# C2000_M3_USB_Type0_Registers register map
Vendor: Texas Instruments
Peripheral module from a debugger description file (folder C2000).
Address unit: 16 bits
Registers are 8-bit, read-write, no defined reset value unless marked. A register's access mark holds for its fields unless they carry their own. Offsets are as the file gives them; lines under a group give offsets from that group; [hi:lo] are bit positions; {n}, {i} and the like mark numbered series; 'fields as' and 'values as' point back to an identical list; <NAME> marks a mode.

## USB0 — Univeral Serial Bus register offsets
0x00 USB_FADDR — USB Device Functional Address
  [6:0] USB_FADDR — Function Address
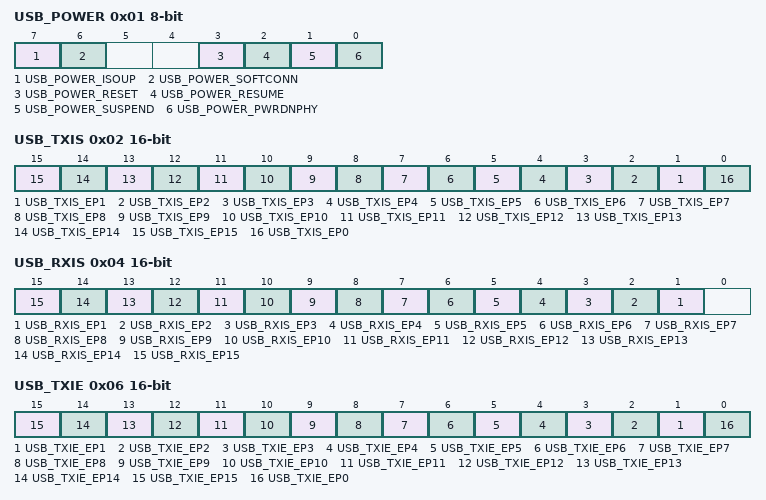
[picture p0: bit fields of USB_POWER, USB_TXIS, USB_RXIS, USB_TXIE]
0x01 USB_POWER
  [7] USB_POWER_ISOUP — Isochronous Update
  [6] USB_POWER_SOFTCONN — Soft Connect/Disconnect
  [3] USB_POWER_RESET — RESET Signaling
  [2] USB_POWER_RESUME — RESUME Signaling
  [1] USB_POWER_SUSPEND — SUSPEND Mode
  [0] USB_POWER_PWRDNPHY — Power Down PHY
0x02 USB_TXIS 16-bit ro — USB Transmit Interrupt Status
  [n] USB_TXIS_EP{n} (n=1..15) — TX Endpoint {n} Interrupt
  [0] USB_TXIS_EP0 — TX and RX Endpoint 0 Interrupt
0x04 USB_RXIS 16-bit ro — USB Receive Interrupt Status
  [n] USB_RXIS_EP{n} (n=1..15) — RX Endpoint {n} Interrupt
0x06 USB_TXIE 16-bit — USB Transmit Interrupt Enable
  [n] USB_TXIE_EP{n} (n=1..15) — TX Endpoint {n} Interrupt Enable
  [0] USB_TXIE_EP0 — TX and RX Endpoint 0 Interrupt Enable
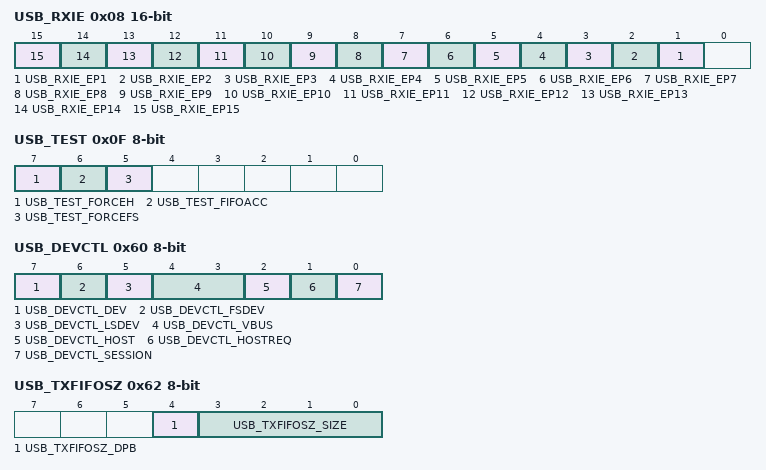
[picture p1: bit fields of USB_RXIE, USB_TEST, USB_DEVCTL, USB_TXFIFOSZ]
0x08 USB_RXIE 16-bit — USB Receive Interrupt Enable
  [n] USB_RXIE_EP{n} (n=1..15) — RX Endpoint {n} Interrupt Enable
0x0A USB_IS ro — USB General Interrupt Status
  [7] USB_IS_VBUSERR — VBUS Error
  [6] USB_IS_SESREQ — SESSION REQUEST
  [5] USB_IS_DISCON — Session Disconnect
  [4] USB_IS_CONN — Session Connect
  [3] USB_IS_SOF — Start of Frame
  [2] USB_IS_BABBLE — Babble Detected
  [2] USB_IS_RESET — RESET Signaling Detected
  [1] USB_IS_RESUME — RESUME Signaling Detected
  [0] USB_IS_SUSPEND — SUSPEND Signaling Detected
0x0B USB_IE — USB Interrupt Enable
  [7] USB_IE_VBUSERR — Enable VBUS Error Interrupt
  [6] USB_IE_SESREQ — Enable Session Request
  [5] USB_IE_DISCON — Enable Disconnect Interrupt
  [4] USB_IE_CONN — Enable Connect Interrupt
  [3] USB_IE_SOF — Enable Start-of-Frame Interrupt
  [2] USB_IE_BABBLE — Enable Babble Interrupt
  [2] USB_IE_RESET — Enable RESET Interrupt
  [1] USB_IE_RESUME — Enable RESUME Interrupt
  [0] USB_IE_SUSPND — Enable SUSPEND Interrupt
0x0C USB_FRAME 16-bit ro — USB Frame Value
  [10:0] USB_FRAME — Frame Number
0x0E USB_EPIDX — USB Endpoint Index
  [3:0] USB_EPIDX_EPIDX — Endpoint Index
0x0F USB_TEST — USB Test Mode
  [7] USB_TEST_FORCEH — Force Host Mode
  [6] USB_TEST_FIFOACC — FIFO Access
  [5] USB_TEST_FORCEFS — Force Full-Speed Mode
{0x20+4i} USB_FIFO{i} 32-bit (i=0..15) — USB FIFO Endpoint {i}
  [31:0] USB_FIFO{i}_EPDATA — Endpoint Data
0x60 USB_DEVCTL — USB Device Control
  [7] USB_DEVCTL_DEV — Device Mode
  [6] USB_DEVCTL_FSDEV — Full-Speed Device Detected
  [5] USB_DEVCTL_LSDEV — Low-Speed Device Detected
  [4:3] USB_DEVCTL_VBUS — VBUS Level
    0=USB_DEVCTL_VBUS_NONE (Below SessionEnd); 1=USB_DEVCTL_VBUS_SEND (Above SessionEnd, below AValid); 2=USB_DEVCTL_VBUS_AVALID (Above AValid, below VBUSValid); 3=USB_DEVCTL_VBUS_VALID (Above VBUSValid)
  [2] USB_DEVCTL_HOST — Host Mode
  [1] USB_DEVCTL_HOSTREQ — Host Request
  [0] USB_DEVCTL_SESSION — Session Start/End
0x62 USB_TXFIFOSZ — USB Transmit Dynamic FIFO Sizing
  [4] USB_TXFIFOSZ_DPB — Double Packet Buffer Support
  [3:0] USB_TXFIFOSZ_SIZE — Max Packet Size
    0=8; 1=16; 2=32; 3=64; 4=128; 5=256; 6=512; 7=1024; 8=2048
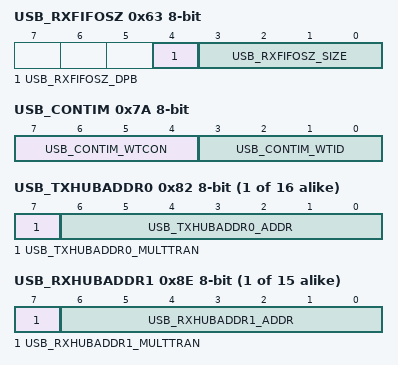
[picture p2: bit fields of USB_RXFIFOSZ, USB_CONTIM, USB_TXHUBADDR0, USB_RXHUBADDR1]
0x63 USB_RXFIFOSZ — USB Receive Dynamic FIFO Sizing
  [4] USB_RXFIFOSZ_DPB — Double Packet Buffer Support
  [3:0] USB_RXFIFOSZ_SIZE — Max Packet Size
    0=8; 1=16; 2=32; 3=64; 4=128; 5=256; 6=512; 7=1024; 8=2048
0x64 USB_TXFIFOADD 16-bit — USB Transmit FIFO Start Address
  [8:0] USB_TXFIFOADD_ADDR — Transmit/Receive Start Address
0x66 USB_RXFIFOADD 16-bit — USB Receive FIFO Start Address
  [8:0] USB_RXFIFOADD_ADDR — Transmit/Receive Start Address
0x7A USB_CONTIM — USB Connect Timing
  [7:4] USB_CONTIM_WTCON — Connect Wait
  [3:0] USB_CONTIM_WTID — Wait ID
0x7B USB_VPLEN — USB OTG VBUS Pulse Timing
  [7:0] USB_VPLEN_VPLEN — VBUS Pulse Length
0x7D USB_FSEOF — USB Full-Speed Last Transaction to End of Frame Timing
  [7:0] USB_FSEOF_FSEOFG — Full-Speed End-of-Frame Gap
0x7E USB_LSEOF — USB Low-Speed Last Transaction to End of Frame Timing
  [7:0] USB_LSEOF_LSEOFG — Low-Speed End-of-Frame Gap
{0x80+8i} USB_TXFUNCADDR{i} (i=0..15) — USB Transmit Functional Address Endpoint {i}
  [6:0] USB_TXFUNCADDR{i}_ADDR — Device Address
{0x82+8i} USB_TXHUBADDR{i} (i=0..15) — USB Transmit Hub Address Endpoint {i}
  [7] USB_TXHUBADDR{i}_MULTTRAN — Multiple Translators
  [6:0] USB_TXHUBADDR{i}_ADDR — Hub Address
{0x83+8i} USB_TXHUBPORT{i} (i=0..15) — USB Transmit Hub Port Endpoint {i}
  [6:0] USB_TXHUBPORT{i}_PORT — Hub Port
{0x84+8i} USB_RXFUNCADDR{i} (i=1..15) — USB Receive Functional Address Endpoint {i}
  [6:0] USB_RXFUNCADDR{i}_ADDR — Device Address
{0x86+8i} USB_RXHUBADDR{i} (i=1..15) — USB Receive Hub Address Endpoint {i}
  [7] USB_RXHUBADDR{i}_MULTTRAN — Multiple Translators
  [6:0] USB_RXHUBADDR{i}_ADDR — Hub Address
{0x87+8i} USB_RXHUBPORT{i} (i=1..15) — USB Receive Hub Port Endpoint {i}
  [6:0] USB_RXHUBPORT{i}_PORT — Hub Port
0x102 USB_CSRL0 wo — USB Control and Status Endpoint 0 Low
  [7] USB_CSRL0_NAKTO — NAK Timeout
  [7] USB_CSRL0_SETENDC — Setup End Clear
  [6] USB_CSRL0_STATUS — STATUS Packet
  [6] USB_CSRL0_RXRDYC — RXRDY Clear
  [5] USB_CSRL0_REQPKT — Request Packet
  [5] USB_CSRL0_STALL — Send Stall
  [4] USB_CSRL0_SETEND — Setup End
  [4] USB_CSRL0_ERROR — Error
  [3] USB_CSRL0_DATAEND — Data End
  [3] USB_CSRL0_SETUP — Setup Packet
  [2] USB_CSRL0_STALLED — Endpoint Stalled
  [1] USB_CSRL0_TXRDY — Transmit Packet Ready
  [0] USB_CSRL0_RXRDY — Receive Packet Ready
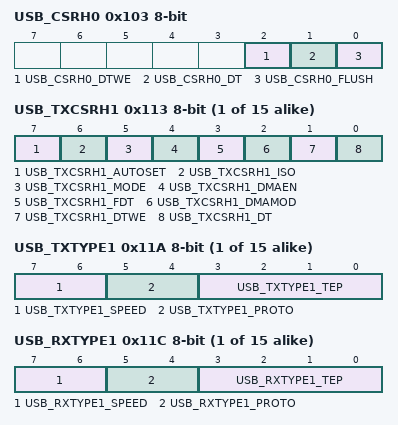
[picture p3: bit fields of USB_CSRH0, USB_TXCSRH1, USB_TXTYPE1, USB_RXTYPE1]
0x103 USB_CSRH0 wo — USB Control and Status Endpoint 0 High
  [2] USB_CSRH0_DTWE — Data Toggle Write Enable
  [1] USB_CSRH0_DT — Data Toggle
  [0] USB_CSRH0_FLUSH — Flush FIFO
0x108 USB_COUNT0 ro — USB Receive Byte Count Endpoint 0
  [6:0] USB_COUNT0_COUNT — FIFO Count
0x10A USB_TYPE0 — USB Type Endpoint 0
  [7:6] USB_TYPE0_SPEED — Operating Speed
    2=USB_TYPE0_SPEED_FULL (Full); 3=USB_TYPE0_SPEED_LOW (Low)
0x10B USB_NAKLMT — USB NAK Limit
  [4:0] USB_NAKLMT_NAKLMT — EP0 NAK Limit
{0x100+0x10*i} USB_TXMAXP{i} 16-bit (i=1..15) — USB Maximum Transmit Data Endpoint {i}
  [10:0] USB_TXMAXP{i}_MAXLOAD — Maximum Payload
0x112 USB_TXCSRL1 — USB Transmit Control and Status Endpoint 1 Low
  [7] USB_TXCSRL1_NAKTO — NAK Timeout
  [6] USB_TXCSRL1_CLRDT — Clear Data Toggle
  [5] USB_TXCSRL1_STALLED — Endpoint Stalled
  [4] USB_TXCSRL1_STALL — Send STALL
  [4] USB_TXCSRL1_SETUP — Setup Packet
  [3] USB_TXCSRL1_FLUSH — Flush FIFO
  [2] USB_TXCSRL1_ERROR — Error
  [2] USB_TXCSRL1_UNDRN — Underrun
  [1] USB_TXCSRL1_FIFONE — FIFO Not Empty
  [0] USB_TXCSRL1_TXRDY — Transmit Packet Ready
{0x103+0x10*i} USB_TXCSRH{i} (i=1..15) — USB Transmit Control and Status Endpoint {i} High
  [7] USB_TXCSRH{i}_AUTOSET — Auto Set
  [6] USB_TXCSRH{i}_ISO — Isochronous Transfers
  [5] USB_TXCSRH{i}_MODE — Mode
  [4] USB_TXCSRH{i}_DMAEN — DMA Request Enable
  [3] USB_TXCSRH{i}_FDT — Force Data Toggle
  [2] USB_TXCSRH{i}_DMAMOD — DMA Request Mode
  [1] USB_TXCSRH{i}_DTWE — Data Toggle Write Enable
  [0] USB_TXCSRH{i}_DT — Data Toggle
{0x104+0x10*i} USB_RXMAXP{i} 16-bit (i=1..15) — USB Maximum Receive Data Endpoint {i}
  [10:0] USB_RXMAXP{i}_MAXLOAD — Maximum Payload
0x116 USB_RXCSRL1 — USB Receive Control and Status Endpoint 1 Low
  [7] USB_RXCSRL1_CLRDT — Clear Data Toggle
  [6] USB_RXCSRL1_STALLED — Endpoint Stalled
  [5] USB_RXCSRL1_STALL — Send STALL
  [5] USB_RXCSRL1_REQPKT — Request Packet
  [4] USB_RXCSRL1_FLUSH — Flush FIFO
  [3] USB_RXCSRL1_DATAERR — Data Error
  [3] USB_RXCSRL1_NAKTO — NAK Timeout
  [2] USB_RXCSRL1_OVER — Overrun
  [2] USB_RXCSRL1_ERROR — Error
  [1] USB_RXCSRL1_FULL — FIFO Full
  [0] USB_RXCSRL1_RXRDY — Receive Packet Ready
{0x107+0x10*i} USB_RXCSRH{i} (i=1..6) — USB Receive Control and Status Endpoint {i} High
  [7] USB_RXCSRH{i}_AUTOCL — Auto Clear
  [6] USB_RXCSRH{i}_AUTORQ — Auto Request
  [6] USB_RXCSRH{i}_ISO — Isochronous Transfers
  [5] USB_RXCSRH{i}_DMAEN — DMA Request Enable
  [4] USB_RXCSRH{i}_DISNYET — Disable NYET
  [4] USB_RXCSRH{i}_PIDERR — PID Error
  [3] USB_RXCSRH{i}_DMAMOD — DMA Request Mode
  [2] USB_RXCSRH{i}_DTWE — Data Toggle Write Enable
  [1] USB_RXCSRH{i}_DT — Data Toggle
{0x108+0x10*i} USB_RXCOUNT{i} 16-bit ro (i=1..15) — USB Receive Byte Count Endpoint {i}
  [12:0] USB_RXCOUNT{i}_COUNT — Receive Packet Count
{0x10A+0x10*i} USB_TXTYPE{i} (i=1..15) — USB Host Transmit Configure Type Endpoint {i}
  [7:6] USB_TXTYPE{i}_SPEED — Operating Speed
    0=USB_TXTYPE{i}_SPEED_DFLT (Default); 2=USB_TXTYPE{i}_SPEED_FULL (Full); 3=USB_TXTYPE{i}_SPEED_LOW (Low)
  [5:4] USB_TXTYPE{i}_PROTO — Protocol
    0=USB_TXTYPE{i}_PROTO_CTRL (Control); 1=USB_TXTYPE{i}_PROTO_ISOC (Isochronous); 2=USB_TXTYPE{i}_PROTO_BULK (Bulk); 3=USB_TXTYPE{i}_PROTO_INT (Interrupt)
  [3:0] USB_TXTYPE{i}_TEP — Target Endpoint Number
{0x10B+0x10*i} USB_TXINTERVAL{i} (i=1..15) — USB Host Transmit Interval Endpoint {i}
  [7:0] USB_TXINTERVAL{i}_TXPOLL — TX Polling
{0x10B+0x10*i} USB_TXINTERVAL{i} (i=1..15) — USB Host Transmit Interval Endpoint {i}
  [7:0] USB_TXINTERVAL{i}_NAKLMT — NAK Limit
{0x10C+0x10*i} USB_RXTYPE{i} (i=1..15) — USB Host Configure Receive Type Endpoint {i}
  [7:6] USB_RXTYPE{i}_SPEED — Operating Speed
    0=USB_RXTYPE{i}_SPEED_DFLT (Default); 2=USB_RXTYPE{i}_SPEED_FULL (Full); 3=USB_RXTYPE{i}_SPEED_LOW (Low)
  [5:4] USB_RXTYPE{i}_PROTO — Protocol
    0=USB_RXTYPE{i}_PROTO_CTRL (Control); 1=USB_RXTYPE{i}_PROTO_ISOC (Isochronous); 2=USB_RXTYPE{i}_PROTO_BULK (Bulk); 3=USB_RXTYPE{i}_PROTO_INT (Interrupt)
  [3:0] USB_RXTYPE{i}_TEP — Target Endpoint Number
{0x10D+0x10*i} USB_RXINTERVAL{i} (i=1..15) — USB Host Receive Polling Interval Endpoint {i}
  [7:0] USB_RXINTERVAL{i}_TXPOLL — RX Polling
{0x10D+0x10*i} USB_RXINTERVAL{i} (i=1..15) — USB Host Receive Polling Interval Endpoint {i}
  [7:0] USB_RXINTERVAL{i}_NAKLMT — NAK Limit
{0x102+0x10*i} USB_TXCSRL{i} (i=2..5) — USB Transmit Control and Status Endpoint {i} Low
  [7] USB_TXCSRL{i}_NAKTO — NAK Timeout
  [6] USB_TXCSRL{i}_CLRDT — Clear Data Toggle
  [5] USB_TXCSRL{i}_STALLED — Endpoint Stalled
  [4] USB_TXCSRL{i}_SETUP — Setup Packet
  [4] USB_TXCSRL{i}_STALL — Send STALL
  [3] USB_TXCSRL{i}_FLUSH — Flush FIFO
  [2] USB_TXCSRL{i}_ERROR — Error
  [2] USB_TXCSRL{i}_UNDRN — Underrun
  [1] USB_TXCSRL{i}_FIFONE — FIFO Not Empty
  [0] USB_TXCSRL{i}_TXRDY — Transmit Packet Ready
0x126 USB_RXCSRL2 — USB Receive Control and Status Endpoint 2 Low
  [7] USB_RXCSRL2_CLRDT — Clear Data Toggle
  [6] USB_RXCSRL2_STALLED — Endpoint Stalled
  [5] USB_RXCSRL2_REQPKT — Request Packet
  [5] USB_RXCSRL2_STALL — Send STALL
  [4] USB_RXCSRL2_FLUSH — Flush FIFO
  [3] USB_RXCSRL2_DATAERR — Data Error
  [3] USB_RXCSRL2_NAKTO — NAK Timeout
  [2] USB_RXCSRL2_ERROR — Error
  [2] USB_RXCSRL2_OVER — Overrun
  [1] USB_RXCSRL2_FULL — FIFO Full
  [0] USB_RXCSRL2_RXRDY — Receive Packet Ready
0x136 USB_RXCSRL3 — USB Receive Control and Status Endpoint 3 Low
  [7] USB_RXCSRL3_CLRDT — Clear Data Toggle
  [6] USB_RXCSRL3_STALLED — Endpoint Stalled
  [5] USB_RXCSRL3_STALL — Send STALL
  [5] USB_RXCSRL3_REQPKT — Request Packet
  [4] USB_RXCSRL3_FLUSH — Flush FIFO
  [3] USB_RXCSRL3_DATAERR — Data Error
  [3] USB_RXCSRL3_NAKTO — NAK Timeout
  [2] USB_RXCSRL3_ERROR — Error
  [2] USB_RXCSRL3_OVER — Overrun
  [1] USB_RXCSRL3_FULL — FIFO Full
  [0] USB_RXCSRL3_RXRDY — Receive Packet Ready
0x146 USB_RXCSRL4 — USB Receive Control and Status Endpoint 4 Low
  [7] USB_RXCSRL4_CLRDT — Clear Data Toggle
  [6] USB_RXCSRL4_STALLED — Endpoint Stalled
  [5] USB_RXCSRL4_STALL — Send STALL
  [5] USB_RXCSRL4_REQPKT — Request Packet
  [4] USB_RXCSRL4_FLUSH — Flush FIFO
  [3] USB_RXCSRL4_NAKTO — NAK Timeout
  [3] USB_RXCSRL4_DATAERR — Data Error
  [2] USB_RXCSRL4_OVER — Overrun
  [2] USB_RXCSRL4_ERROR — Error
  [1] USB_RXCSRL4_FULL — FIFO Full
  [0] USB_RXCSRL4_RXRDY — Receive Packet Ready
0x156 USB_RXCSRL5 — USB Receive Control and Status Endpoint 5 Low
  [7] USB_RXCSRL5_CLRDT — Clear Data Toggle
  [6] USB_RXCSRL5_STALLED — Endpoint Stalled
  [5] USB_RXCSRL5_STALL — Send STALL
  [5] USB_RXCSRL5_REQPKT — Request Packet
  [4] USB_RXCSRL5_FLUSH — Flush FIFO
  [3] USB_RXCSRL5_NAKTO — NAK Timeout
  [3] USB_RXCSRL5_DATAERR — Data Error
  [2] USB_RXCSRL5_ERROR — Error
  [2] USB_RXCSRL5_OVER — Overrun
  [1] USB_RXCSRL5_FULL — FIFO Full
  [0] USB_RXCSRL5_RXRDY — Receive Packet Ready
{0x102+0x10*i} USB_TXCSRL{i} (i=6..8) — USB Transmit Control and Status Endpoint {i} Low
  [7] USB_TXCSRL{i}_NAKTO — NAK Timeout
  [6] USB_TXCSRL{i}_CLRDT — Clear Data Toggle
  [5] USB_TXCSRL{i}_STALLED — Endpoint Stalled
  [4] USB_TXCSRL{i}_STALL — Send STALL
  [4] USB_TXCSRL{i}_SETUP — Setup Packet
  [3] USB_TXCSRL{i}_FLUSH — Flush FIFO
  [2] USB_TXCSRL{i}_ERROR — Error
  [2] USB_TXCSRL{i}_UNDRN — Underrun
  [1] USB_TXCSRL{i}_FIFONE — FIFO Not Empty
  [0] USB_TXCSRL{i}_TXRDY — Transmit Packet Ready
0x166 USB_RXCSRL6 — USB Receive Control and Status Endpoint 6 Low
  [7] USB_RXCSRL6_CLRDT — Clear Data Toggle
  [6] USB_RXCSRL6_STALLED — Endpoint Stalled
  [5] USB_RXCSRL6_REQPKT — Request Packet
  [5] USB_RXCSRL6_STALL — Send STALL
  [4] USB_RXCSRL6_FLUSH — Flush FIFO
  [3] USB_RXCSRL6_NAKTO — NAK Timeout
  [3] USB_RXCSRL6_DATAERR — Data Error
  [2] USB_RXCSRL6_ERROR — Error
  [2] USB_RXCSRL6_OVER — Overrun
  [1] USB_RXCSRL6_FULL — FIFO Full
  [0] USB_RXCSRL6_RXRDY — Receive Packet Ready
0x176 USB_RXCSRL7 — USB Receive Control and Status Endpoint 7 Low
  [7] USB_RXCSRL7_CLRDT — Clear Data Toggle
  [6] USB_RXCSRL7_STALLED — Endpoint Stalled
  [5] USB_RXCSRL7_REQPKT — Request Packet
  [5] USB_RXCSRL7_STALL — Send STALL
  [4] USB_RXCSRL7_FLUSH — Flush FIFO
  [3] USB_RXCSRL7_DATAERR — Data Error
  [3] USB_RXCSRL7_NAKTO — NAK Timeout
  [2] USB_RXCSRL7_ERROR — Error
  [2] USB_RXCSRL7_OVER — Overrun
  [1] USB_RXCSRL7_FULL — FIFO Full
  [0] USB_RXCSRL7_RXRDY — Receive Packet Ready
0x177 USB_RXCSRH7 — USB Receive Control and Status Endpoint 7 High
  [7] USB_RXCSRH7_AUTOCL — Auto Clear
  [6] USB_RXCSRH7_ISO — Isochronous Transfers
  [6] USB_RXCSRH7_AUTORQ — Auto Request
  [5] USB_RXCSRH7_DMAEN — DMA Request Enable
  [4] USB_RXCSRH7_PIDERR — PID Error
  [4] USB_RXCSRH7_DISNYET — Disable NYET
  [3] USB_RXCSRH7_DMAMOD — DMA Request Mode
  [2] USB_RXCSRH7_DTWE — Data Toggle Write Enable
  [1] USB_RXCSRH7_DT — Data Toggle
0x186 USB_RXCSRL8 — USB Receive Control and Status Endpoint 8 Low
  [7] USB_RXCSRL8_CLRDT — Clear Data Toggle
  [6] USB_RXCSRL8_STALLED — Endpoint Stalled
  [5] USB_RXCSRL8_STALL — Send STALL
  [5] USB_RXCSRL8_REQPKT — Request Packet
  [4] USB_RXCSRL8_FLUSH — Flush FIFO
  [3] USB_RXCSRL8_NAKTO — NAK Timeout
  [3] USB_RXCSRL8_DATAERR — Data Error
  [2] USB_RXCSRL8_OVER — Overrun
  [2] USB_RXCSRL8_ERROR — Error
  [1] USB_RXCSRL8_FULL — FIFO Full
  [0] USB_RXCSRL8_RXRDY — Receive Packet Ready
0x187 USB_RXCSRH8 — USB Receive Control and Status Endpoint 8 High
  [7] USB_RXCSRH8_AUTOCL — Auto Clear
  [6] USB_RXCSRH8_AUTORQ — Auto Request
  [6] USB_RXCSRH8_ISO — Isochronous Transfers
  [5] USB_RXCSRH8_DMAEN — DMA Request Enable
  [4] USB_RXCSRH8_DISNYET — Disable NYET
  [4] USB_RXCSRH8_PIDERR — PID Error
  [3] USB_RXCSRH8_DMAMOD — DMA Request Mode
  [2] USB_RXCSRH8_DTWE — Data Toggle Write Enable
  [1] USB_RXCSRH8_DT — Data Toggle
0x192 USB_TXCSRL9 — USB Transmit Control and Status Endpoint 9 Low
  [7] USB_TXCSRL9_NAKTO — NAK Timeout
  [6] USB_TXCSRL9_CLRDT — Clear Data Toggle
  [5] USB_TXCSRL9_STALLED — Endpoint Stalled
  [4] USB_TXCSRL9_SETUP — Setup Packet
  [4] USB_TXCSRL9_STALL — Send STALL
  [3] USB_TXCSRL9_FLUSH — Flush FIFO
  [2] USB_TXCSRL9_ERROR — Error
  [2] USB_TXCSRL9_UNDRN — Underrun
  [1] USB_TXCSRL9_FIFONE — FIFO Not Empty
  [0] USB_TXCSRL9_TXRDY — Transmit Packet Ready
0x196 USB_RXCSRL9 — USB Receive Control and Status Endpoint 9 Low
  [7] USB_RXCSRL9_CLRDT — Clear Data Toggle
  [6] USB_RXCSRL9_STALLED — Endpoint Stalled
  [5] USB_RXCSRL9_STALL — Send STALL
  [5] USB_RXCSRL9_REQPKT — Request Packet
  [4] USB_RXCSRL9_FLUSH — Flush FIFO
  [3] USB_RXCSRL9_DATAERR — Data Error
  [3] USB_RXCSRL9_NAKTO — NAK Timeout
  [2] USB_RXCSRL9_ERROR — Error
  [2] USB_RXCSRL9_OVER — Overrun
  [1] USB_RXCSRL9_FULL — FIFO Full
  [0] USB_RXCSRL9_RXRDY — Receive Packet Ready
0x197 USB_RXCSRH9 — USB Receive Control and Status Endpoint 9 High
  [7] USB_RXCSRH9_AUTOCL — Auto Clear
  [6] USB_RXCSRH9_ISO — Isochronous Transfers
  [6] USB_RXCSRH9_AUTORQ — Auto Request
  [5] USB_RXCSRH9_DMAEN — DMA Request Enable
  [4] USB_RXCSRH9_PIDERR — PID Error
  [4] USB_RXCSRH9_DISNYET — Disable NYET
  [3] USB_RXCSRH9_DMAMOD — DMA Request Mode
  [2] USB_RXCSRH9_DTWE — Data Toggle Write Enable
  [1] USB_RXCSRH9_DT — Data Toggle
0x1A2 USB_TXCSRL10 — USB Transmit Control and Status Endpoint 10 Low
  [7] USB_TXCSRL10_NAKTO — NAK Timeout
  [6] USB_TXCSRL10_CLRDT — Clear Data Toggle
  [5] USB_TXCSRL10_STALLED — Endpoint Stalled
  [4] USB_TXCSRL10_SETUP — Setup Packet
  [4] USB_TXCSRL10_STALL — Send STALL
  [3] USB_TXCSRL10_FLUSH — Flush FIFO
  [2] USB_TXCSRL10_UNDRN — Underrun
  [2] USB_TXCSRL10_ERROR — Error
  [1] USB_TXCSRL10_FIFONE — FIFO Not Empty
  [0] USB_TXCSRL10_TXRDY — Transmit Packet Ready
0x1A6 USB_RXCSRL10 — USB Receive Control and Status Endpoint 10 Low
  [7] USB_RXCSRL10_CLRDT — Clear Data Toggle
  [6] USB_RXCSRL10_STALLED — Endpoint Stalled
  [5] USB_RXCSRL10_STALL — Send STALL
  [5] USB_RXCSRL10_REQPKT — Request Packet
  [4] USB_RXCSRL10_FLUSH — Flush FIFO
  [3] USB_RXCSRL10_NAKTO — NAK Timeout
  [3] USB_RXCSRL10_DATAERR — Data Error
  [2] USB_RXCSRL10_OVER — Overrun
  [2] USB_RXCSRL10_ERROR — Error
  [1] USB_RXCSRL10_FULL — FIFO Full
  [0] USB_RXCSRL10_RXRDY — Receive Packet Ready
0x1A7 USB_RXCSRH10 — USB Receive Control and Status Endpoint 10 High
  [7] USB_RXCSRH10_AUTOCL — Auto Clear
  [6] USB_RXCSRH10_AUTORQ — Auto Request
  [6] USB_RXCSRH10_ISO — Isochronous Transfers
  [5] USB_RXCSRH10_DMAEN — DMA Request Enable
  [4] USB_RXCSRH10_PIDERR — PID Error
  [4] USB_RXCSRH10_DISNYET — Disable NYET
  [3] USB_RXCSRH10_DMAMOD — DMA Request Mode
  [2] USB_RXCSRH10_DTWE — Data Toggle Write Enable
  [1] USB_RXCSRH10_DT — Data Toggle
0x1B2 USB_TXCSRL11 — USB Transmit Control and Status Endpoint 11 Low
  [7] USB_TXCSRL11_NAKTO — NAK Timeout
  [6] USB_TXCSRL11_CLRDT — Clear Data Toggle
  [5] USB_TXCSRL11_STALLED — Endpoint Stalled
  [4] USB_TXCSRL11_STALL — Send STALL
  [4] USB_TXCSRL11_SETUP — Setup Packet
  [3] USB_TXCSRL11_FLUSH — Flush FIFO
  [2] USB_TXCSRL11_ERROR — Error
  [2] USB_TXCSRL11_UNDRN — Underrun
  [1] USB_TXCSRL11_FIFONE — FIFO Not Empty
  [0] USB_TXCSRL11_TXRDY — Transmit Packet Ready
0x1B6 USB_RXCSRL11 — USB Receive Control and Status Endpoint 11 Low
  [7] USB_RXCSRL11_CLRDT — Clear Data Toggle
  [6] USB_RXCSRL11_STALLED — Endpoint Stalled
  [5] USB_RXCSRL11_STALL — Send STALL
  [5] USB_RXCSRL11_REQPKT — Request Packet
  [4] USB_RXCSRL11_FLUSH — Flush FIFO
  [3] USB_RXCSRL11_DATAERR — Data Error
  [3] USB_RXCSRL11_NAKTO — NAK Timeout
  [2] USB_RXCSRL11_OVER — Overrun
  [2] USB_RXCSRL11_ERROR — Error
  [1] USB_RXCSRL11_FULL — FIFO Full
  [0] USB_RXCSRL11_RXRDY — Receive Packet Ready
0x1B7 USB_RXCSRH11 — USB Receive Control and Status Endpoint 11 High
  [7] USB_RXCSRH11_AUTOCL — Auto Clear
  [6] USB_RXCSRH11_ISO — Isochronous Transfers
  [6] USB_RXCSRH11_AUTORQ — Auto Request
  [5] USB_RXCSRH11_DMAEN — DMA Request Enable
  [4] USB_RXCSRH11_DISNYET — Disable NYET
  [4] USB_RXCSRH11_PIDERR — PID Error
  [3] USB_RXCSRH11_DMAMOD — DMA Request Mode
  [2] USB_RXCSRH11_DTWE — Data Toggle Write Enable
  [1] USB_RXCSRH11_DT — Data Toggle
0x1C2 USB_TXCSRL12 — USB Transmit Control and Status Endpoint 12 Low
  [7] USB_TXCSRL12_NAKTO — NAK Timeout
  [6] USB_TXCSRL12_CLRDT — Clear Data Toggle
  [5] USB_TXCSRL12_STALLED — Endpoint Stalled
  [4] USB_TXCSRL12_SETUP — Setup Packet
  [4] USB_TXCSRL12_STALL — Send STALL
  [3] USB_TXCSRL12_FLUSH — Flush FIFO
  [2] USB_TXCSRL12_UNDRN — Underrun
  [2] USB_TXCSRL12_ERROR — Error
  [1] USB_TXCSRL12_FIFONE — FIFO Not Empty
  [0] USB_TXCSRL12_TXRDY — Transmit Packet Ready
0x1C6 USB_RXCSRL12 — USB Receive Control and Status Endpoint 12 Low
  [7] USB_RXCSRL12_CLRDT — Clear Data Toggle
  [6] USB_RXCSRL12_STALLED — Endpoint Stalled
  [5] USB_RXCSRL12_STALL — Send STALL
  [5] USB_RXCSRL12_REQPKT — Request Packet
  [4] USB_RXCSRL12_FLUSH — Flush FIFO
  [3] USB_RXCSRL12_NAKTO — NAK Timeout
  [3] USB_RXCSRL12_DATAERR — Data Error
  [2] USB_RXCSRL12_ERROR — Error
  [2] USB_RXCSRL12_OVER — Overrun
  [1] USB_RXCSRL12_FULL — FIFO Full
  [0] USB_RXCSRL12_RXRDY — Receive Packet Ready
0x1C7 USB_RXCSRH12 — USB Receive Control and Status Endpoint 12 High
  [7] USB_RXCSRH12_AUTOCL — Auto Clear
  [6] USB_RXCSRH12_ISO — Isochronous Transfers
  [6] USB_RXCSRH12_AUTORQ — Auto Request
  [5] USB_RXCSRH12_DMAEN — DMA Request Enable
  [4] USB_RXCSRH12_PIDERR — PID Error
  [4] USB_RXCSRH12_DISNYET — Disable NYET
  [3] USB_RXCSRH12_DMAMOD — DMA Request Mode
  [2] USB_RXCSRH12_DTWE — Data Toggle Write Enable
  [1] USB_RXCSRH12_DT — Data Toggle
0x1D2 USB_TXCSRL13 — USB Transmit Control and Status Endpoint 13 Low
  [7] USB_TXCSRL13_NAKTO — NAK Timeout
  [6] USB_TXCSRL13_CLRDT — Clear Data Toggle
  [5] USB_TXCSRL13_STALLED — Endpoint Stalled
  [4] USB_TXCSRL13_SETUP — Setup Packet
  [4] USB_TXCSRL13_STALL — Send STALL
  [3] USB_TXCSRL13_FLUSH — Flush FIFO
  [2] USB_TXCSRL13_UNDRN — Underrun
  [2] USB_TXCSRL13_ERROR — Error
  [1] USB_TXCSRL13_FIFONE — FIFO Not Empty
  [0] USB_TXCSRL13_TXRDY — Transmit Packet Ready
0x1D6 USB_RXCSRL13 — USB Receive Control and Status Endpoint 13 Low
  [7] USB_RXCSRL13_CLRDT — Clear Data Toggle
  [6] USB_RXCSRL13_STALLED — Endpoint Stalled
  [5] USB_RXCSRL13_REQPKT — Request Packet
  [5] USB_RXCSRL13_STALL — Send STALL
  [4] USB_RXCSRL13_FLUSH — Flush FIFO
  [3] USB_RXCSRL13_NAKTO — NAK Timeout
  [3] USB_RXCSRL13_DATAERR — Data Error
  [2] USB_RXCSRL13_OVER — Overrun
  [2] USB_RXCSRL13_ERROR — Error
  [1] USB_RXCSRL13_FULL — FIFO Full
  [0] USB_RXCSRL13_RXRDY — Receive Packet Ready
0x1D7 USB_RXCSRH13 — USB Receive Control and Status Endpoint 13 High
  [7] USB_RXCSRH13_AUTOCL — Auto Clear
  [6] USB_RXCSRH13_ISO — Isochronous Transfers
  [6] USB_RXCSRH13_AUTORQ — Auto Request
  [5] USB_RXCSRH13_DMAEN — DMA Request Enable
  [4] USB_RXCSRH13_DISNYET — Disable NYET
  [4] USB_RXCSRH13_PIDERR — PID Error
  [3] USB_RXCSRH13_DMAMOD — DMA Request Mode
  [2] USB_RXCSRH13_DTWE — Data Toggle Write Enable
  [1] USB_RXCSRH13_DT — Data Toggle
0x1E2 USB_TXCSRL14 — USB Transmit Control and Status Endpoint 14 Low
  [7] USB_TXCSRL14_NAKTO — NAK Timeout
  [6] USB_TXCSRL14_CLRDT — Clear Data Toggle
  [5] USB_TXCSRL14_STALLED — Endpoint Stalled
  [4] USB_TXCSRL14_STALL — Send STALL
  [4] USB_TXCSRL14_SETUP — Setup Packet
  [3] USB_TXCSRL14_FLUSH — Flush FIFO
  [2] USB_TXCSRL14_ERROR — Error
  [2] USB_TXCSRL14_UNDRN — Underrun
  [1] USB_TXCSRL14_FIFONE — FIFO Not Empty
  [0] USB_TXCSRL14_TXRDY — Transmit Packet Ready
0x1E6 USB_RXCSRL14 — USB Receive Control and Status Endpoint 14 Low
  [7] USB_RXCSRL14_CLRDT — Clear Data Toggle
  [6] USB_RXCSRL14_STALLED — Endpoint Stalled
  [5] USB_RXCSRL14_REQPKT — Request Packet
  [5] USB_RXCSRL14_STALL — Send STALL
  [4] USB_RXCSRL14_FLUSH — Flush FIFO
  [3] USB_RXCSRL14_DATAERR — Data Error
  [3] USB_RXCSRL14_NAKTO — NAK Timeout
  [2] USB_RXCSRL14_OVER — Overrun
  [2] USB_RXCSRL14_ERROR — Error
  [1] USB_RXCSRL14_FULL — FIFO Full
  [0] USB_RXCSRL14_RXRDY — Receive Packet Ready
0x1E7 USB_RXCSRH14 — USB Receive Control and Status Endpoint 14 High
  [7] USB_RXCSRH14_AUTOCL — Auto Clear
  [6] USB_RXCSRH14_AUTORQ — Auto Request
  [6] USB_RXCSRH14_ISO — Isochronous Transfers
  [5] USB_RXCSRH14_DMAEN — DMA Request Enable
  [4] USB_RXCSRH14_PIDERR — PID Error
  [4] USB_RXCSRH14_DISNYET — Disable NYET
  [3] USB_RXCSRH14_DMAMOD — DMA Request Mode
  [2] USB_RXCSRH14_DTWE — Data Toggle Write Enable
  [1] USB_RXCSRH14_DT — Data Toggle
0x1F2 USB_TXCSRL15 — USB Transmit Control and Status Endpoint 15 Low
  [7] USB_TXCSRL15_NAKTO — NAK Timeout
  [6] USB_TXCSRL15_CLRDT — Clear Data Toggle
  [5] USB_TXCSRL15_STALLED — Endpoint Stalled
  [4] USB_TXCSRL15_SETUP — Setup Packet
  [4] USB_TXCSRL15_STALL — Send STALL
  [3] USB_TXCSRL15_FLUSH — Flush FIFO
  [2] USB_TXCSRL15_UNDRN — Underrun
  [2] USB_TXCSRL15_ERROR — Error
  [1] USB_TXCSRL15_FIFONE — FIFO Not Empty
  [0] USB_TXCSRL15_TXRDY — Transmit Packet Ready
0x1F6 USB_RXCSRL15 — USB Receive Control and Status Endpoint 15 Low
  [7] USB_RXCSRL15_CLRDT — Clear Data Toggle
  [6] USB_RXCSRL15_STALLED — Endpoint Stalled
  [5] USB_RXCSRL15_STALL — Send STALL
  [5] USB_RXCSRL15_REQPKT — Request Packet
  [4] USB_RXCSRL15_FLUSH — Flush FIFO
  [3] USB_RXCSRL15_DATAERR — Data Error
  [3] USB_RXCSRL15_NAKTO — NAK Timeout
  [2] USB_RXCSRL15_ERROR — Error
  [2] USB_RXCSRL15_OVER — Overrun
  [1] USB_RXCSRL15_FULL — FIFO Full
  [0] USB_RXCSRL15_RXRDY — Receive Packet Ready
0x1F7 USB_RXCSRH15 — USB Receive Control and Status Endpoint 15 High
  [7] USB_RXCSRH15_AUTOCL — Auto Clear
  [6] USB_RXCSRH15_AUTORQ — Auto Request
  [6] USB_RXCSRH15_ISO — Isochronous Transfers
  [5] USB_RXCSRH15_DMAEN — DMA Request Enable
  [4] USB_RXCSRH15_PIDERR — PID Error
  [4] USB_RXCSRH15_DISNYET — Disable NYET
  [3] USB_RXCSRH15_DMAMOD — DMA Request Mode
  [2] USB_RXCSRH15_DTWE — Data Toggle Write Enable
  [1] USB_RXCSRH15_DT — Data Toggle
{0x300+4i} USB_RQPKTCOUNT{i} 16-bit (i=1..3) — USB Request Packet Count in Block Transfer Endpoint {i}
  [15:0] USB_RQPKTCOUNT{i} — Block Transfer Packet Count
{0x300+4i} USB_RQPKTCOUNT{i} 16-bit (i=4..15) — USB Request Packet Count in Block Transfer Endpoint {i}
  [15:0] USB_RQPKTCOUNT{i}_COUNT — Block Transfer Packet Count
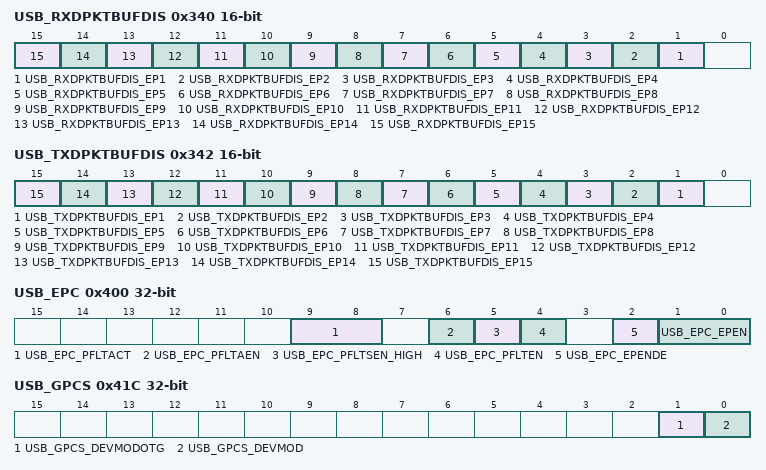
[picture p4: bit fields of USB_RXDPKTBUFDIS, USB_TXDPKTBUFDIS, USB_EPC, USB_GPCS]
0x340 USB_RXDPKTBUFDIS 16-bit — USB Receive Double Packet Buffer Disable
  [n] USB_RXDPKTBUFDIS_EP{n} (n=1..15) — EP{n} RX Double-Packet Buffer Disable
0x342 USB_TXDPKTBUFDIS 16-bit — USB Transmit Double Packet Buffer Disable
  [n] USB_TXDPKTBUFDIS_EP{n} (n=1..15) — EP{n} TX Double-Packet Buffer Disable
0x400 USB_EPC 32-bit — USB External Power Control
  [9:8] USB_EPC_PFLTACT — Power Fault Action
    0=USB_EPC_PFLTACT_UNCHG (Unchanged); 1=USB_EPC_PFLTACT_TRIS (Tristate); 2=USB_EPC_PFLTACT_LOW (Low); 3=USB_EPC_PFLTACT_HIGH (High)
  [6] USB_EPC_PFLTAEN — Power Fault Action Enable
  [5] USB_EPC_PFLTSEN_HIGH — Power Fault Sense
  [4] USB_EPC_PFLTEN — Power Fault Input Enable
  [2] USB_EPC_EPENDE — EPEN Drive Enable
  [1:0] USB_EPC_EPEN — External Power Supply Enable Configuration
    0=USB_EPC_EPEN_LOW (Power Enable Active Low); 1=USB_EPC_EPEN_HIGH (Power Enable Active High); 2=USB_EPC_EPEN_VBLOW (Power Enable High if VBUS Low); 3=USB_EPC_EPEN_VBHIGH (Power Enable High if VBUS High)
0x404 USB_EPCRIS 32-bit ro — USB External Power Control Raw Interrupt Status
  [0] USB_EPCRIS_PF — USB Power Fault Interrupt Status
0x408 USB_EPCIM 32-bit — USB External Power Control Interrupt Mask
  [0] USB_EPCIM_PF — USB Power Fault Interrupt Mask
0x40C USB_EPCISC 32-bit — USB External Power Control Interrupt Status and Clear
  [0] USB_EPCISC_PF — USB Power Fault Interrupt Status and Clear
0x410 USB_DRRIS 32-bit ro — USB Device RESUME Raw Interrupt Status
  [0] USB_DRRIS_RESUME — RESUME Interrupt Status
0x414 USB_DRIM 32-bit — USB Device RESUME Interrupt Mask
  [0] USB_DRIM_RESUME — RESUME Interrupt Mask
0x418 USB_DRISC 32-bit wo — USB Device RESUME Interrupt Status and Clear
  [0] USB_DRISC_RESUME — RESUME Interrupt Status and Clear
0x41C USB_GPCS 32-bit — USB General-Purpose Control and Status
  [1] USB_GPCS_DEVMODOTG — Enable Device Mode
  [0] USB_GPCS_DEVMOD — Device Mode
0x430 USB_VDC 32-bit — USB VBUS Droop Control
  [0] USB_VDC_VBDEN — VBUS Droop Enable
0x434 USB_VDCRIS 32-bit ro — USB VBUS Droop Control Raw Interrupt Status
  [0] USB_VDCRIS_VD — VBUS Droop Raw Interrupt Status
0x438 USB_VDCIM 32-bit — USB VBUS Droop Control Interrupt Mask
  [0] USB_VDCIM_VD — VBUS Droop Interrupt Mask
0x43C USB_VDCISC 32-bit — USB VBUS Droop Control Interrupt Status and Clear
  [0] USB_VDCISC_VD — VBUS Droop Interrupt Status and Clear
0x444 USB_IDVRIS 32-bit ro — USB ID Valid Detect Raw Interrupt Status
  [0] USB_IDVRIS_ID — ID Valid Detect Raw Interrupt Status
0x448 USB_IDVIM 32-bit — USB ID Valid Detect Interrupt Mask
  [0] USB_IDVIM_ID — ID Valid Detect Interrupt Mask
0x44C USB_IDVISC 32-bit — USB ID Valid Detect Interrupt Status and Clear
  [0] USB_IDVISC_ID — ID Valid Detect Interrupt Status and Clear
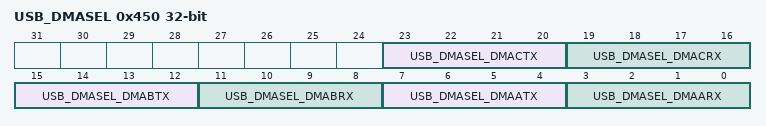
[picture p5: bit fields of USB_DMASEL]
0x450 USB_DMASEL 32-bit — USB DMA Select
  [23:20] USB_DMASEL_DMACTX — DMA C TX Select
  [19:16] USB_DMASEL_DMACRX — DMA C RX Select
  [15:12] USB_DMASEL_DMABTX — DMA B TX Select
  [11:8] USB_DMASEL_DMABRX — DMA B RX Select
  [7:4] USB_DMASEL_DMAATX — DMA A TX Select
  [3:0] USB_DMASEL_DMAARX — DMA A RX Select
